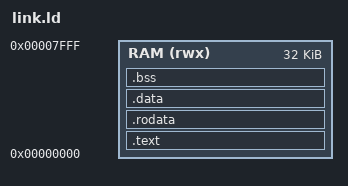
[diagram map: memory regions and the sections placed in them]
/* PicoRV32, code and data in BSRAM at 0 (trs.md 8.2). The image is loaded into
   BSRAM by the bitstream or the loader, so .data needs no copy. */
OUTPUT_ARCH(riscv)
ENTRY(_start)

MEMORY
{
    RAM (rwx) : ORIGIN = 0x00000000, LENGTH = 32K
}

STACK_SIZE = 2K;

SECTIONS
{
    .text : {
        KEEP(*(.text.start))
        *(.text .text.*)
    } > RAM

    .rodata : ALIGN(4) {
        *(.rodata .rodata.*)
        *(.srodata .srodata.*)
    } > RAM

    .data : ALIGN(4) {
        *(.data .data.*)
        __global_pointer$ = . + 0x800;
        *(.sdata .sdata.*)
    } > RAM

    .bss (NOLOAD) : ALIGN(4) {
        __bss_start = .;
        *(.sbss .sbss.*)
        *(.bss .bss.*)
        *(COMMON)
        . = ALIGN(4);
        __bss_end = .;
    } > RAM

    __stack_top = ORIGIN(RAM) + LENGTH(RAM);
    ASSERT(__bss_end + STACK_SIZE <= __stack_top, "no room for the stack")
}
